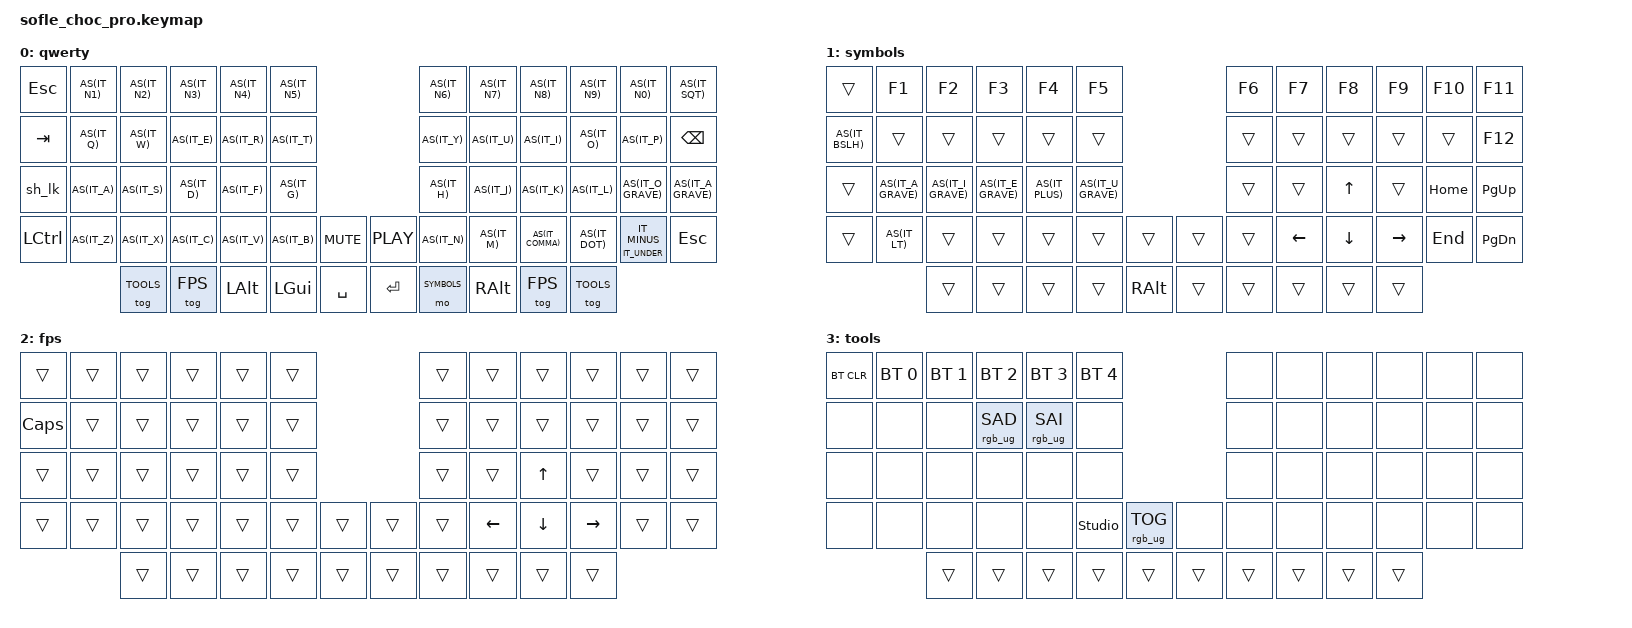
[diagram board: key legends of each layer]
/*
* Copyright (c) 2020 The ZMK Contributors
*
* SPDX-License-Identifier: MIT
*/

#include <behaviors.dtsi>
#include <dt-bindings/zmk/keys.h>
#include <dt-bindings/zmk/bt.h>
#include <dt-bindings/zmk/rgb.h>
#include <dt-bindings/zmk/ext_power.h>
#include <locale/keys_it.h>

#define QWERTY 0
#define SYMBOLS 1
#define FPS 2
#define TOOLS 3
#define AS(keycode) &as LS(keycode) keycode

/ {

      behaviors {
        as: auto_shift {
            compatible = "zmk,behavior-hold-tap";
            #binding-cells = <2>;
            tapping-term-ms = <200>;
            quick-tap-ms = <500>;
            flavor = "balanced";
            bindings = <&kp>, <&kp>;
        };
	as_2: as_2 {
            compatible = "zmk,behavior-hold-tap";
            #binding-cells = <2>;
            tapping-term-ms = <200>;
            quick-tap-ms = <500>;
            flavor = "balanced";
            bindings = <&kp>, <&kp>;
	};
        sh_lk: shift_lock {
            compatible = "zmk,behavior-tap-dance";
            #binding-cells = <0>;
            tapping-term-ms = <200>;
            bindings = <&kp LSHFT>, <&kp CAPS>;
        };
	rgb_encoder_left: rgb_encoder_left {
            compatible = "zmk,behavior-sensor-rotate";
            #sensor-binding-cells = <0>;
            bindings = <&rgb_ug RGB_BRD>, <&rgb_ug RGB_BRI>;
        };
	rgb_encoder_right: rgb_encoder_right {
            compatible = "zmk,behavior-sensor-rotate";
            #sensor-binding-cells = <0>;
            bindings = <&rgb_ug RGB_HUD>, <&rgb_ug RGB_HUI>;
        };
    };

  keymap {
    compatible = "zmk,keymap";

    qwerty_layer {
      display-name = "qwerty";
      // ------------------------------------------------------------------------------------------------------------
      // |   `   |  1  |  2  |  3   |  4   |  5   |                   |  6   |  7    |  8    |  9   |   0   |   `   |
      // |  ESC  |  Q  |  W  |  E   |  R   |  T   |                   |  Y   |  U    |  I    |  O   |   P   | BKSPC |
      // |  TAB  |  A  |  S  |  D   |  F   |  G   |                   |  H   |  J    |  K    |  L   |   ;   |   '   |
      // | SHIFT |  Z  |  X  |  C   |  V   |  B   |  MUTE  |  | PLAY  |  N   |  M    |  ,    |  .   |   /   | SHIFT |
      //               | GUI | ALT  | CTRL | LOWER|  ENTER |  | SPACE | RAISE| CTRL  | ALT   | GUI  |
      bindings = <
        &kp ESC    AS(IT_N1)  AS(IT_N2)   AS(IT_N3)  AS(IT_N4)  AS(IT_N5)                                   AS(IT_N6)    AS(IT_N7)  AS(IT_N8)     AS(IT_N9)   AS(IT_N0)                AS(IT_SQT)
        &kp TAB    AS(IT_Q)   AS(IT_W)    AS(IT_E)   AS(IT_R)   AS(IT_T)                                    AS(IT_Y)     AS(IT_U)   AS(IT_I)      AS(IT_O)    AS(IT_P)                 &kp BSPC
        &sh_lk     AS(IT_A)   AS(IT_S)    AS(IT_D)   AS(IT_F)   AS(IT_G)                                    AS(IT_H)     AS(IT_J)   AS(IT_K)      AS(IT_L)    AS(IT_O_GRAVE)           AS(IT_A_GRAVE)
        &kp LCTRL  AS(IT_Z)   AS(IT_X)    AS(IT_C)   AS(IT_V)   AS(IT_B)   &kp C_MUTE           &kp C_PLAY  AS(IT_N)     AS(IT_M)   AS(IT_COMMA)  AS(IT_DOT)  &as_2 IT_UNDER IT_MINUS  &kp ESC
                              &tog TOOLS  &tog FPS   &kp LALT   &kp LGUI   &kp SPACE            &kp RET     &mo SYMBOLS  &kp RALT   &tog FPS      &tog TOOLS
      >;

      sensor-bindings = <&inc_dec_kp C_VOL_DN C_VOL_UP &inc_dec_kp C_PREV C_NEXT>;
    };

    symbols_layer {
      display-name = "symbols";
      // ------------------------------------------------------------------------------------------------------------
      // |       |  F1 |  F2 |  F3  |  F4  |  F5  |                   |  F6  |  F7   |  F8   |  F9  |  F10  |  F11  |
      // |   `   |  1  |  2  |  3   |  4   |  5   |                   |  6   |  7    |  8    |  9   |   0   |  F12  |
      // |       |  !  |  @  |  #   |  $   |  %   |                   |  ^   |  &    |  *    |  (   |   )   |   |   |
      // |       |  =  |  -  |  +   |  {   |  }   |        |  |       |  [   |  ]    |  ;    |  :   |   \   |       |
      //               |     |      |      |      |        |  |       |      |       |       |      |
      bindings = <
        &trans       &kp F1          &kp F2          &kp F3          &kp F4       &kp F5                                          &kp F6  &kp F7    &kp F8    &kp F9     &kp F10   &kp F11
        AS(IT_BSLH)  &trans          &trans          &trans          &trans       &trans                                          &trans  &trans    &trans    &trans     &trans    &kp F12
        &trans       AS(IT_A_GRAVE)  AS(IT_I_GRAVE)  AS(IT_E_GRAVE)  AS(IT_PLUS)  AS(IT_U_GRAVE)                                  &trans  &trans    &kp UP    &trans     &kp HOME  &kp PG_UP
        &trans       AS(IT_LT)       &trans          &trans          &trans       &trans          &trans                  &trans  &trans  &kp LEFT  &kp DOWN  &kp RIGHT  &kp END   &kp PG_DN
                                     &trans          &trans          &trans       &trans          &kp RALT                &trans  &trans  &trans    &trans    &trans
      >;

    };

    fn_layer {
      display-name = "fps";
      // ------------------------------------------------------------------------------------------------------------
      // | BTCLR | BT1  | BT2  |  BT3  |  BT4  |  BT5 |                |      |      |       |      |       |       |
      // |       | INS  | PSCR | GUI   |       |      |                | PGUP |      |   ^   |      |       |       |
      // |       | ALT  | CTRL | SHIFT |       | CAPS |                | PGDN |   <- |   v   |  ->  |  DEL  | BKSPC |
      // |       | UNDO | CUT  | COPY  | PASTE |      |      |  |      |      |      |       |      |       |       |
      //                |      |       |       |      |      |  |      |      |      |       |      |
      bindings = <
        &trans    &trans  &trans  &trans  &trans  &trans                        &trans  &trans    &trans    &trans     &trans   &trans
        &kp CAPS  &trans  &trans  &trans  &trans  &trans                        &trans  &trans    &trans    &trans     &trans   &trans
        &trans    &trans  &trans  &trans  &trans  &trans                        &trans  &trans    &kp UP    &trans     &trans   &trans
        &trans    &trans  &trans  &trans  &trans  &trans  &trans        &trans  &trans  &kp LEFT  &kp DOWN  &kp RIGHT  &trans   &trans
                          &trans  &trans  &trans  &trans  &trans        &trans  &trans  &trans    &trans    &trans
      >;

    };

    tools_layer {
      // ----------------------------------------------------------------------------------------------------------------------------
      // | BTCLR  |  BT1    |  BT2    |   BT3   |   BT4   |   BT5   |                  |      |      |       |      |       |       |
      // | EXTPWR | RGB_HUD | RGB_HUI | RGB_SAD | RGB_SAI | RGB_EFF |                  |      |      |       |      |       |       |
      // |        | RGB_BRD | RGB_BRI |         |         |         |                  |      |      |       |      |       |       |
      // |        |         |         |         |         |         | RGB_TOG | |      |      |      |       |      |       |       |
      //                    |         |         |         |         |         | |      |      |      |       |      |
      display-name = "tools";
      bindings = <
        &bt BT_CLR  &bt BT_SEL 0  &bt BT_SEL 1  &bt BT_SEL 2     &bt BT_SEL 3     &bt BT_SEL 4                                                     &none   &none   &none   &none  &none  &none
        &none       &none         &none         &rgb_ug RGB_SAD  &rgb_ug RGB_SAI  &none                                                            &none   &none   &none   &none  &none  &none
        &none       &none         &none         &none            &none            &none                                                            &none   &none   &none   &none  &none  &none
        &none       &none         &none         &none            &none            &studio_unlock    &rgb_ug RGB_TOG                &none   &none   &none   &none   &none   &none  &none
                        	  &trans        &trans           &trans           &trans            &trans                         &trans  &trans  &trans  &trans  &trans >;

      sensor-bindings = <&rgb_encoder_left &rgb_encoder_right>;
    };
  };
};
